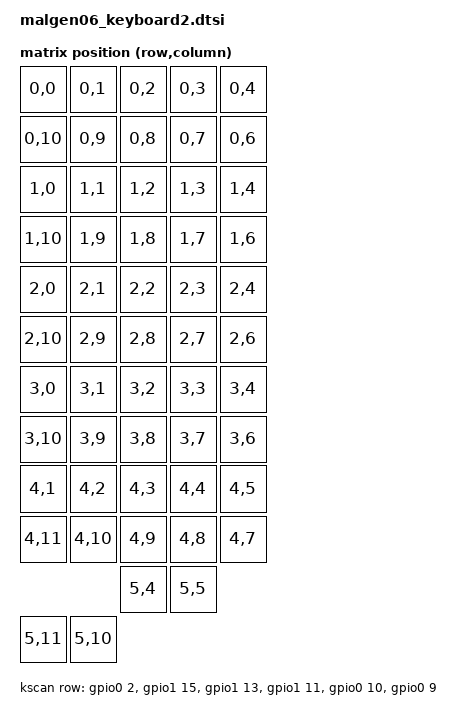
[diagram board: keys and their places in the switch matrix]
// This file was generated from a template. Edit it to match your keyboard.
// See https://zmk.dev/docs/development/hardware-integration/new-shield for more
// instructions.

#include <dt-bindings/zmk/matrix_transform.h>

#include "malgen06_keyboard2-layouts.dtsi"

/ {
    chosen {
        zmk,physical-layout = &default_layout;
    };

    kscan: kscan {
        // If the hardware does not use a switch matrix, change this to the
        // appropriate driver and update the properties below to match.
        // See https://zmk.dev/docs/config/kscan for supported key scan drivers.
        compatible = "zmk,kscan-gpio-matrix";
        // Set this to "col2row" or "row2col" to match the hardware. If using
        // "row2col", change the col-gpios in the _left.overlay and _right.overlay
        // files to (GPIO_ACTIVE_HIGH | GPIO_PULL_DOWN) and the row-gpios here to
        // GPIO_ACTIVE_HIGH.
        diode-direction = "row2col";
        wakeup-source;

        // Replace these comments with the GPIO pins in the matrix.
        // See https://zmk.dev/docs/development/hardware-integration/new-shield#shield-overlays
        row-gpios
            = <&gpio0 2 GPIO_ACTIVE_HIGH>
            , <&gpio1 15 GPIO_ACTIVE_HIGH>
            , <&gpio1 13 GPIO_ACTIVE_HIGH>
            , <&gpio1 11 GPIO_ACTIVE_HIGH>
            , <&gpio0 10 GPIO_ACTIVE_HIGH>
            , <&gpio0 9 GPIO_ACTIVE_HIGH>
            ;
    };

    default_transform: default_transform {
        compatible = "zmk,matrix-transform";
        columns = <12>;
        rows = <6>;

     map = <
        // Left half                              Right half
         // Row 0
         RC(0, 0) RC(0, 1) RC(0, 2) RC(0, 3) RC(0, 4)
         RC(0,10) RC(0, 9) RC(0, 8) RC(0, 7) RC(0, 6)

         // Row 1
         RC(1, 0) RC(1, 1) RC(1, 2) RC(1, 3) RC(1, 4)
         RC(1,10) RC(1, 9) RC(1, 8) RC(1, 7) RC(1, 6)

         // Row 2
         RC(2, 0) RC(2, 1) RC(2, 2) RC(2, 3) RC(2, 4)
         RC(2,10) RC(2, 9) RC(2, 8) RC(2, 7) RC(2, 6)

         // Row 3
         RC(3, 0) RC(3, 1) RC(3, 2) RC(3, 3) RC(3, 4)
         RC(3,10) RC(3, 9) RC(3, 8) RC(3, 7) RC(3, 6)

         // Row 4
         RC(4, 1) RC(4, 2) RC(4, 3) RC(4, 4) RC(4, 5)
         RC(4,11) RC(4,10) RC(4, 9) RC(4, 8) RC(4, 7)

         // Row 5
                             RC(5, 4) RC(5, 5)
           RC(5,11) RC(5,10)
        >;
    };
};
